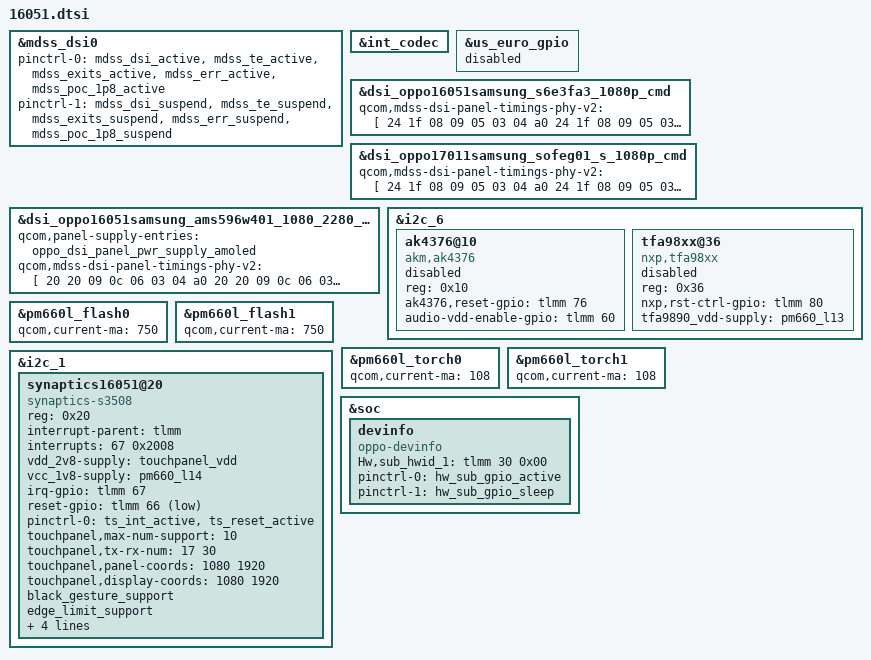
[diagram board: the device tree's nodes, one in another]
// SPDX-License-Identifier: GPL-2.0
/*
 * OPPO R11 (16051) 设备特有 dtsi
 *
 * 聚合共性 (oppo-sdm660-common.dtsi) + 承载 16051 特有硬件 overlay。
 * 由入口 sdm660-pm660a-mtp-16051.dts 末尾 #include。
 * 来源: oppo 4.4 16051/sdm660-mtp.dtsi + sdm660-pinctrl.dtsi
 *
 * 16051 特有项:
 *   - 触摸: synaptics16051@20 (synaptics-s3508, tx-rx 17x30, 1080x1920,
 *     button-type <2 0x05>, button-TRx <1 2>, spurious_fingerprint 启用)
 *   - VOOC: stm8s vooc-fw-type=<5> (唯一为 5) + vooc-low-temp=<120>; bq27541/pic16f
 *   - 指纹: goodix_fp 不启用 (oppo 4.4 源码注释掉); fpc 由 common 提供
 *   - devinfo: 仅 sub_hwid_1 (gpio30, 1 个 GPIO); 无 RFver_gpio
 *   - 无 RFver pinctrl group
 */
#include "../dsi-panel-oppo17011samsung_sofeg01_1080p_cmd-16051-16103-16118.dtsi"
#include "../dsi-panel-oppo17021samsung_sofeg01_1080p_cmd-16051-16103-16118.dtsi"
#include "oppo-sdm660-common.dtsi"
#include "../dsi-panel-oppo16051samsung_ams596w401_1080_2280_cmd.dtsi"

/* ===== 16051 特有硬件 overlay ===== */

&mdss_dsi0 {
	pinctrl-names = "mdss_default", "mdss_sleep";
	pinctrl-0 = <&mdss_dsi_active &mdss_te_active
			&mdss_exits_active &mdss_err_active
			&mdss_poc_1p8_active>;
	pinctrl-1 = <&mdss_dsi_suspend &mdss_te_suspend
			&mdss_exits_suspend &mdss_err_suspend
			&mdss_poc_1p8_suspend>;
};

&int_codec {
	/delete-property/ qcom,us-euro-gpios;
};

&us_euro_gpio {
	status = "disabled";
};

/* Panel PHY v2 timing overrides from the 16051 stock mdss panel table. */
&dsi_oppo16051samsung_s6e3fa3_1080p_cmd {
	qcom,mdss-dsi-panel-timings-phy-v2 = [
		24 1f 08 09 05 03 04 a0
		24 1f 08 09 05 03 04 a0
		24 1f 08 09 05 03 04 a0
		24 1f 08 09 05 03 04 a0
		24 1a 08 09 05 03 04 a0];
};

&dsi_oppo17011samsung_sofeg01_s_1080p_cmd {
	qcom,mdss-dsi-panel-timings-phy-v2 = [
		24 1f 08 09 05 03 04 a0
		24 1f 08 09 05 03 04 a0
		24 1f 08 09 05 03 04 a0
		24 1f 08 09 05 03 04 a0
		24 1b 08 09 05 03 04 a0];
};

&dsi_oppo16051samsung_ams596w401_1080_2280_cmd {
	qcom,panel-supply-entries = <&oppo_dsi_panel_pwr_supply_amoled>;
	qcom,mdss-dsi-panel-timings-phy-v2 = [
		20 20 09 0c 06 03 04 a0
		20 20 09 0c 06 03 04 a0
		20 20 09 0c 06 03 04 a0
		20 20 09 0c 06 03 04 a0
		20 1e 09 0a 06 03 04 a0];
};

/* 16051 uses the GPIO-powered AK4376 and NXP TFA98xx amplifier. */
&i2c_6 {
	status = "okay";

	ak4376@10 {
		compatible = "akm,ak4376";
		reg = <0x10>;
		ak4376,reset-gpio = <&tlmm 76 0x00>;
		audio-vdd-enable-gpio = <&tlmm 60 0x00>;
		/* No akm,ak4376 codec or SDM660 machine-link consumer in 4.19. */
		status = "disabled";
	};

	tfa98xx@36 {
		compatible = "nxp,tfa98xx";
		reg = <0x36>;
		nxp,rst-ctrl-gpio = <&tlmm 80 0x00>;
		tfa9890_vdd-supply = <&pm660_l13>;
		/* tfa9879 is a different codec/DAI; do not bind it as tfa98xx. */
		status = "disabled";
	};
};

/* Match the stock PM660L flash/torch startup currents. */
&pm660l_flash0 {
	qcom,current-ma = <750>;
};

&pm660l_flash1 {
	qcom,current-ma = <750>;
};

&pm660l_torch0 {
	qcom,current-ma = <108>;
};

&pm660l_torch1 {
	qcom,current-ma = <108>;
};

/* --- 触摸屏 synaptics16051@20 (synaptics-s3508, tx-rx 17x30, 1080x1920) --- */
&i2c_1 {
	status = "okay";
	synaptics16051@20 {
		compatible = "synaptics-s3508";
		reg = <0x20>;

		/* Interrupt && Irq-gpio */
		interrupt-parent = <&tlmm>;
		interrupts = <67 0x2008>;

		/* Power Config */
		vdd_2v8-supply = <&touchpanel_vdd>;
		vcc_1v8-supply = <&pm660_l14>;

		/* Other HW Resource */
		irq-gpio = <&tlmm 67 0x2008>;
		reset-gpio = <&tlmm 66 0x1>;
		pinctrl-names = "default";
		pinctrl-0 = <&ts_int_active &ts_reset_active>;

		touchpanel,max-num-support = <10>;
		touchpanel,tx-rx-num = <17 30>;
		touchpanel,panel-coords = <1080 1920>;
		touchpanel,display-coords = <1080 1920>;

		/* SW Support Feature Control */
		black_gesture_support;
		edge_limit_support;
		spurious_fingerprint_support;
		smart_gesture_support;

		touchpanel,button-type = <2 0x05>;
		touchpanel.button-TRx = <1 2>;
	};
};

/* --- devinfo（16051: 仅 sub_hwid_1=gpio30，无 sub_hwid_2/RFver_gpio）---
 * 注: goodix_fp 在 oppo 4.4 16051 源码中为注释状态，故此处不写该节点
 * （fpc_fpc1020 / oppo_fp_common 由 oppo-sdm660-common.dtsi 共性提供）。
 */
&soc {
	devinfo {
		compatible = "oppo-devinfo";
		Hw,sub_hwid_1 = <&tlmm 30 0x00>;
		pinctrl-names = "default", "hw_sub_gpio_sleep";
		pinctrl-0 = <&hw_sub_gpio_active>;
		pinctrl-1 = <&hw_sub_gpio_sleep>;
	};
};

#include "oppo-camera-16051.dtsi"
